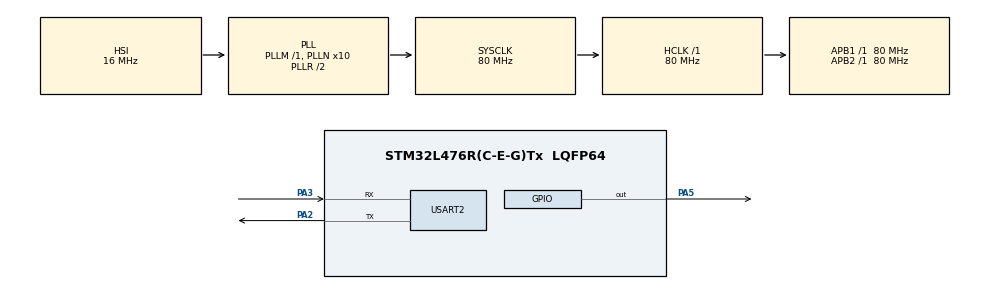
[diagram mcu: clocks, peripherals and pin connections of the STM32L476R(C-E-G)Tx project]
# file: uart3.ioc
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Mcu.Family=STM32L4
RCC.MSI_VALUE=4000000
RCC.PLLSourceVirtual=RCC_PLLSOURCE_HSI
NVIC.DMA1_Channel6_IRQn=true\:0\:0\:false\:false\:true\:false\:true
RCC.CortexFreq_Value=80000000
Dma.USART2_RX.0.Direction=DMA_PERIPH_TO_MEMORY
VP_TIM16_VS_ClockSourceINT.Mode=Enable_Timer
NVIC.USART2_IRQn=true\:0\:0\:false\:false\:true\:true\:true
RCC.SYSCLKSource=RCC_SYSCLKSOURCE_PLLCLK
ProjectManager.StackSize=0x400
Dma.USART2_RX.0.Mode=DMA_NORMAL
PA3.Mode=Asynchronous
ProjectManager.TargetToolchain=STM32CubeIDE
Dma.USART2_RX.0.Priority=DMA_PRIORITY_LOW
Dma.USART2_RX.0.PeriphDataAlignment=DMA_PDATAALIGN_BYTE
RCC.HCLKFreq_Value=80000000
RCC.APB2TimFreq_Value=80000000
RCC.USBFreq_Value=64000000
RCC.LSE_VALUE=32768
RCC.AHBFreq_Value=80000000
RCC.PREFETCH_ENABLE=1
PA5.Signal=GPIO_Output
RCC.HSE_VALUE=8000000
board=NUCLEO-L476RG
USART2.VirtualMode-Asynchronous=VM_ASYNC
RCC.VCOOutputFreq_Value=160000000
TIM16.Period=10000-1
RCC.APB2Freq_Value=80000000
Dma.USART2_RX.0.MemDataAlignment=DMA_MDATAALIGN_BYTE
RCC.ADCFreq_Value=64000000
Dma.USART2_RX.0.Instance=DMA1_Channel6
Mcu.Name=STM32L476R(C-E-G)Tx
Dma.USART2_RX.0.MemInc=DMA_MINC_ENABLE
PA2.Signal=USART2_TX
RCC.SYSCLKFreq_VALUE=80000000
Mcu.Package=LQFP64
Dma.USART2_RX.0.PeriphInc=DMA_PINC_DISABLE
ProjectManager.HeapSize=0x200
RCC.HSI_VALUE=16000000
NVIC.TIM1_UP_TIM16_IRQn=true\:0\:0\:false\:false\:true\:true\:true
NVIC.PriorityGroup=NVIC_PRIORITYGROUP_4
RCC.PLLN=10
RCC.APB1TimFreq_Value=80000000
PA2.Mode=Asynchronous
TIM16.Prescaler=8000-1
Dma.Request0=USART2_RX
RCC.APB1Freq_Value=80000000
PA3.Signal=USART2_RX

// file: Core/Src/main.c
/* USER CODE BEGIN Header */
/**
  ******************************************************************************
  * @file           : main.c
  * @brief          : Main program body
  ******************************************************************************
  * @attention
  *
  * <h2><center>&copy; Copyright (c) 2021 STMicroelectronics.
  * All rights reserved.</center></h2>
  *
  * This software component is licensed by ST under BSD 3-Clause license,
  * the "License"; You may not use this file except in compliance with the
  * License. You may obtain a copy of the License at:
  *                        opensource.org/licenses/BSD-3-Clause
  *
  ******************************************************************************
  */
/* USER CODE END Header */
#include "main.h"
#include "stdlib.h"

/* USER CODE BEGIN PD */

#define BUFFER_SIZE 10

/* USER CODE END PD */

TIM_HandleTypeDef htim16;

UART_HandleTypeDef huart2;
DMA_HandleTypeDef hdma_usart2_rx;

/* USER CODE BEGIN PV */
typedef struct Time
{
	uint8_t hour;
	uint8_t minute;
	uint8_t second;
} Time;
typedef struct TimeStr
{
	char hour[BUFFER_SIZE];
	char minute[BUFFER_SIZE];
	char second[BUFFER_SIZE];
} TimeStr;
char buffer[BUFFER_SIZE];
int buffer_index=0;
char START_MESSAGE[350]="\r\nWELCOME!\r\nAVAILABLE COMMANDS:\r\nON - turn on LED\r\nOFF- turn off LED\r\ntoggle - change LED state to oposite\r\nset_time - set current time\r\nstart_time - start the counter\r\nstop_time - stop the counter\r\nhelp - show this message again\r\n";
char NEW_LINE[8]="\r\n<<  ";
const uint8_t ENTER_CHAR = 0x0d;
const uint8_t SEMICOLON_CHAR = 0x3b;
char received;
char on_command[BUFFER_SIZE]="ON";
char off_command[BUFFER_SIZE]="OFF";
char help_command[BUFFER_SIZE]="help";
char toggle_command[BUFFER_SIZE]="toggle";
char time_command[BUFFER_SIZE]="set_time";
char start_command[BUFFER_SIZE]="start_time";
char stop_command[BUFFER_SIZE]="stop_time";
Time time={.hour=0,.minute=0,.second=0};
TimeStr time_str;
uint8_t set_timeON=0;
uint8_t interval_var=0;

/* USER CODE END PV */

void SystemClock_Config(void);
static void MX_GPIO_Init(void);
static void MX_DMA_Init(void);
static void MX_USART2_UART_Init(void);
static void MX_TIM16_Init(void);

int main(void)
{

  /* MCU Configuration--------------------------------------------------------*/

  /* Reset of all peripherals, Initializes the Flash interface and the Systick. */
  HAL_Init();

  /* Configure the system clock */
  SystemClock_Config();

  /* Initialize all configured peripherals */
  MX_GPIO_Init();
  MX_DMA_Init();
  MX_USART2_UART_Init();
  MX_TIM16_Init();
  /* USER CODE BEGIN 2 */
  HAL_UART_Transmit(&huart2,START_MESSAGE, sizeof(START_MESSAGE),100);
  HAL_UART_Transmit(&huart2,NEW_LINE, sizeof(NEW_LINE), 100);
  Clear_Buffer();

//  HAL_UARTEx_ReceiveToIdle_DMA(&huart2, rx_buffer, rx_buff_size);
 // __HAL_DMA_DISABLE_IT(&hdma_usart2_rx,DMA_IT_HT);
  HAL_UART_Receive_IT(&huart2, &received, 1);

  /* USER CODE END 2 */

  /* Infinite loop */
  while (1)
  {

  }
}

void SystemClock_Config(void)
{
  RCC_OscInitTypeDef RCC_OscInitStruct = {0};
  RCC_ClkInitTypeDef RCC_ClkInitStruct = {0};
  RCC_PeriphCLKInitTypeDef PeriphClkInit = {0};

  /** Initializes the RCC Oscillators according to the specified parameters
  * in the RCC_OscInitTypeDef structure.
  */
  RCC_OscInitStruct.OscillatorType = RCC_OSCILLATORTYPE_HSI;
  RCC_OscInitStruct.HSIState = RCC_HSI_ON;
  RCC_OscInitStruct.HSICalibrationValue = RCC_HSICALIBRATION_DEFAULT;
  RCC_OscInitStruct.PLL.PLLState = RCC_PLL_ON;
  RCC_OscInitStruct.PLL.PLLSource = RCC_PLLSOURCE_HSI;
  RCC_OscInitStruct.PLL.PLLM = 1;
  RCC_OscInitStruct.PLL.PLLN = 10;
  RCC_OscInitStruct.PLL.PLLP = RCC_PLLP_DIV7;
  RCC_OscInitStruct.PLL.PLLQ = RCC_PLLQ_DIV2;
  RCC_OscInitStruct.PLL.PLLR = RCC_PLLR_DIV2;
  if (HAL_RCC_OscConfig(&RCC_OscInitStruct) != HAL_OK)
  {
    Error_Handler();
  }
  /** Initializes the CPU, AHB and APB buses clocks
  */
  RCC_ClkInitStruct.ClockType = RCC_CLOCKTYPE_HCLK|RCC_CLOCKTYPE_SYSCLK
                              |RCC_CLOCKTYPE_PCLK1|RCC_CLOCKTYPE_PCLK2;
  RCC_ClkInitStruct.SYSCLKSource = RCC_SYSCLKSOURCE_PLLCLK;
  RCC_ClkInitStruct.AHBCLKDivider = RCC_SYSCLK_DIV1;
  RCC_ClkInitStruct.APB1CLKDivider = RCC_HCLK_DIV1;
  RCC_ClkInitStruct.APB2CLKDivider = RCC_HCLK_DIV1;

  if (HAL_RCC_ClockConfig(&RCC_ClkInitStruct, FLASH_LATENCY_4) != HAL_OK)
  {
    Error_Handler();
  }
  PeriphClkInit.PeriphClockSelection = RCC_PERIPHCLK_USART2;
  PeriphClkInit.Usart2ClockSelection = RCC_USART2CLKSOURCE_PCLK1;
  if (HAL_RCCEx_PeriphCLKConfig(&PeriphClkInit) != HAL_OK)
  {
    Error_Handler();
  }
  /** Configure the main internal regulator output voltage
  */
  if (HAL_PWREx_ControlVoltageScaling(PWR_REGULATOR_VOLTAGE_SCALE1) != HAL_OK)
  {
    Error_Handler();
  }
}

static void MX_TIM16_Init(void)
{

  htim16.Instance = TIM16;
  htim16.Init.Prescaler = 8000-1;
  htim16.Init.CounterMode = TIM_COUNTERMODE_UP;
  htim16.Init.Period = 10000-1;
  htim16.Init.ClockDivision = TIM_CLOCKDIVISION_DIV1;
  htim16.Init.RepetitionCounter = 0;
  htim16.Init.AutoReloadPreload = TIM_AUTORELOAD_PRELOAD_DISABLE;
  if (HAL_TIM_Base_Init(&htim16) != HAL_OK)
  {
    Error_Handler();
  }

}

static void MX_USART2_UART_Init(void)
{

  huart2.Instance = USART2;
  huart2.Init.BaudRate = 115200;
  huart2.Init.WordLength = UART_WORDLENGTH_8B;
  huart2.Init.StopBits = UART_STOPBITS_1;
  huart2.Init.Parity = UART_PARITY_NONE;
  huart2.Init.Mode = UART_MODE_TX_RX;
  huart2.Init.HwFlowCtl = UART_HWCONTROL_NONE;
  huart2.Init.OverSampling = UART_OVERSAMPLING_16;
  huart2.Init.OneBitSampling = UART_ONE_BIT_SAMPLE_DISABLE;
  huart2.AdvancedInit.AdvFeatureInit = UART_ADVFEATURE_NO_INIT;
  if (HAL_UART_Init(&huart2) != HAL_OK)
  {
    Error_Handler();
  }

}

static void MX_DMA_Init(void)
{

  /* DMA controller clock enable */
  __HAL_RCC_DMA1_CLK_ENABLE();

  /* DMA interrupt init */
  /* DMA1_Channel6_IRQn interrupt configuration */
  HAL_NVIC_SetPriority(DMA1_Channel6_IRQn, 0, 0);
  HAL_NVIC_EnableIRQ(DMA1_Channel6_IRQn);

}

static void MX_GPIO_Init(void)
{
  GPIO_InitTypeDef GPIO_InitStruct = {0};

  /* GPIO Ports Clock Enable */
  __HAL_RCC_GPIOA_CLK_ENABLE();

  /*Configure GPIO pin Output Level */
  HAL_GPIO_WritePin(GPIOA, GPIO_PIN_5, GPIO_PIN_RESET);

  /*Configure GPIO pin : PA5 */
  GPIO_InitStruct.Pin = GPIO_PIN_5;
  GPIO_InitStruct.Mode = GPIO_MODE_OUTPUT_PP;
  GPIO_InitStruct.Pull = GPIO_NOPULL;
  GPIO_InitStruct.Speed = GPIO_SPEED_FREQ_LOW;
  HAL_GPIO_Init(GPIOA, &GPIO_InitStruct);

}

/* USER CODE BEGIN 4 */

void Clear_Buffer()
{
	memset(buffer, '\0', BUFFER_SIZE*sizeof(uint8_t));
}

void Update_Time(Time* time)
{
	time->second++;
	if((time->second)>59)
	{
		time->second=0;
		time->minute++;
		if(time->minute>59)
			{
				time->minute=0;
				time->hour++;
				if(time->hour>23)
				{
					time->hour=0;
				}

			}
	}

}

void TimetoString(Time *time,TimeStr*time_str)
{
	itoa(time->hour,time_str->hour,10);
	itoa(time->minute,time_str->minute,10);
	itoa(time->second,time_str->second,10);

}

void Print_Time(TimeStr *time_str)
{

	HAL_UART_Transmit(&huart2, "time: ",6,100);
	HAL_UART_Transmit(&huart2, time_str->hour,2,100);
	HAL_UART_Transmit(&huart2, ":",1,100);
	HAL_UART_Transmit(&huart2, time_str->minute,2,100);
	HAL_UART_Transmit(&huart2, ":",1,100);
	HAL_UART_Transmit(&huart2, time_str->second,2,100);
	HAL_UART_Transmit(&huart2,NEW_LINE, sizeof(NEW_LINE), 100);
}

void StringtoTime(Time *time,TimeStr*time_str)
{
	time->hour=atoi(time_str->hour);
	time->minute=atoi(time_str->minute);
	time->second=atoi(time_str->second);
}

void Handle_Commands()
{
	if(!strcmp(buffer,on_command))
	{
		HAL_GPIO_WritePin(GPIOA, GPIO_PIN_5, 1);
		HAL_UART_Transmit(&huart2, "LED turned on", 13,100);
		HAL_UART_Transmit(&huart2,NEW_LINE, sizeof(NEW_LINE),100);
	}
	else if(!strcmp(buffer,off_command))
	{
		HAL_GPIO_WritePin(GPIOA, GPIO_PIN_5, 0);
		HAL_UART_Transmit(&huart2, "LED turned off ", 14,100);
		HAL_UART_Transmit(&huart2,NEW_LINE, sizeof(NEW_LINE), 100);
	}
	else if(!strcmp(buffer,toggle_command))
	{
		HAL_GPIO_TogglePin(GPIOA, GPIO_PIN_5);
		HAL_UART_Transmit(&huart2, "LED Toggled ", 12,100);
		HAL_UART_Transmit(&huart2,NEW_LINE, sizeof(NEW_LINE), 100);
	}
	else if(!strcmp(buffer,help_command))
	{
		HAL_UART_Transmit(&huart2, START_MESSAGE, sizeof(START_MESSAGE),100);
		HAL_UART_Transmit(&huart2,NEW_LINE, sizeof(NEW_LINE), 100);
	}
	else if(!strcmp(buffer,start_command))
	{
		HAL_TIM_Base_Start_IT(&htim16);
		TimetoString(&time, &time_str);
		Print_Time(&time_str);
		uint8_t interval_var=0;
	}
	else if(!strcmp(buffer,stop_command))
	{
		HAL_TIM_Base_Stop_IT(&htim16);
		uint8_t interval_var=0;

	}
	else if(!strcmp(buffer,time_command))
	{

		HAL_UART_Transmit(&huart2, "Enter time in format <hh:mm:ss>; :",33,100);
		set_timeON=1;
		HAL_UART_Transmit(&huart2,NEW_LINE, sizeof(NEW_LINE), 100);

	}
	else
	{
		HAL_UART_Transmit(&huart2, "Unknown Command", 15,100);
		HAL_UART_Transmit(&huart2,NEW_LINE, sizeof(NEW_LINE), 100);
	}
}

void HAL_TIM_PeriodElapsedCallback (TIM_HandleTypeDef * htim)
{
	if(htim==&htim16)
	{
		Update_Time(&time);

		if(interval_var<9)
		{
			interval_var++;

		}
		else
		{
			TimetoString(&time, &time_str);
			Print_Time(&time_str);
			interval_var=0;

		}

	}
}

void HAL_UART_RxCpltCallback(UART_HandleTypeDef *huart)
{

	if(huart->Instance == USART2)
	{

		if(!strcmp(received,ENTER_CHAR))
		{
			HAL_UART_Transmit(&huart2,NEW_LINE, sizeof(NEW_LINE), 100);
			Handle_Commands();
			Clear_Buffer();
			buffer_index=0;
		}
		else if((set_timeON==1)&&(!strcmp(received,SEMICOLON_CHAR)))
		{
			HAL_UART_Transmit(&huart2,NEW_LINE, sizeof(NEW_LINE), 100);

			memcpy(time_str.hour,buffer,2);
			memcpy(time_str.minute,buffer+3,2);
			memcpy(time_str.second,buffer+6,2);
			set_timeON=0;
			Clear_Buffer();
			buffer_index=0;
			StringtoTime(&time,&time_str);
			TimetoString(&time, &time_str);
			Print_Time(&time_str);
			interval_var=0;
		}

		else
		{
			HAL_UART_Transmit(&huart2,&received, 1, 100);
			//memcpy(buffer+buffer_index,received,1);
			buffer[buffer_index]=received;
			buffer_index++;
		}

		HAL_UART_Receive_IT(&huart2, &received, 1);
		if(buffer_index>BUFFER_SIZE)
		{
			HAL_UART_Transmit(&huart2,NEW_LINE, sizeof(NEW_LINE), 100);
			HAL_UART_Transmit(&huart2,"buffer size exceeded", 30, 100);
			HAL_UART_Transmit(&huart2,NEW_LINE, sizeof(NEW_LINE), 100);
			Handle_Commands();
			Clear_Buffer();
			buffer_index=0;
		}

	}

}

void HAL_USART_TxCpltCallback(UART_HandleTypeDef *huart)
{

}

/* USER CODE END 4 */

void Error_Handler(void)
{
  __disable_irq();
  while (1)
  {
  }
}

/************************ (C) COPYRIGHT STMicroelectronics *****END OF FILE****/
